# STM32L452xx register map
File version: 1.0
Registers are 32-bit, access not given, reset 0x0 unless marked. A register's access mark holds for its fields unless they carry their own. Offsets are from the block's base; [hi:lo] are bit positions; {n}, {i} and the like mark numbered series.

## SAI1
Base 0x40015400
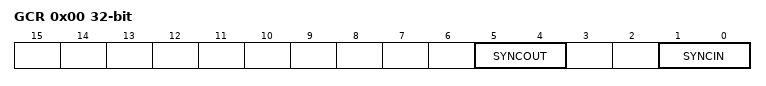
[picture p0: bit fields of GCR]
0x00 GCR
  [5:4] SYNCOUT, [1:0] SYNCIN
0x04 CR1A
0x08 CR2A
0x10 FRCRA
0x1C SLOTRA
0x24 CR1B
0x28 CR2B
0x2C IMRA
0x30 FRCRB
0x3C SLOTRB
0x40 SRA
0x4C IMRB
0x58 CLRFRA
0x60 SRB
0x74 DRA
0x78 CLRFRB
0x94 DRB

## DFSDM1
Base 0x40016000
0x00 CHCFGR10
  [31] DFSDMEN, [31] DFSDMEN, [31] DFSDMEN, [31] DFSDMEN, [31] DFSDMEN, [31] DFSDMEN, [30] CKOUTSRC, [30] CKOUTSRC, [30] CKOUTSRC, [30] CKOUTSRC, [30] CKOUTSRC, [30] CKOUTSRC, [23:22] AWFORD, [23:22] AWFORD, [23:22] AWFORD, [23:22] AWFORD, [23:22] AWFORD, [23:22] AWFORD, [23:16] CKOUTDIV, [20:16] AWFOSR, [23:16] CKOUTDIV, [31:16] INDAT1, [20:16] AWFOSR, [23:16] CKOUTDIV, [31:16] INDAT1, [20:16] AWFOSR, [23:16] CKOUTDIV, [31:16] INDAT1, [20:16] AWFOSR, [31:16] INDAT1, [23:16] CKOUTDIV, [20:16] AWFOSR, [31:16] INDAT1, [23:16] CKOUTDIV, [20:16] AWFOSR, [31:16] INDAT1, [15:14] DATPACK, [15:14] DATPACK, [15:14] DATPACK, [15:14] DATPACK, [15:14] DATPACK, [15:14] DATPACK, [13:12] DATMPX, [15:12] BKSCD, [13:12] DATMPX, [15:12] BKSCD, [13:12] DATMPX, [15:12] BKSCD, [13:12] DATMPX, [15:12] BKSCD, [13:12] DATMPX, [15:12] BKSCD, [13:12] DATMPX, [15:12] BKSCD, [8] CHINSEL, [31:8] OFFSET, [8] CHINSEL, [31:8] OFFSET, [8] CHINSEL, [31:8] OFFSET, [8] CHINSEL, [31:8] OFFSET, [8] CHINSEL, [31:8] OFFSET, [8] CHINSEL, [31:8] OFFSET, [7] CHEN, [7] CHEN, [7] CHEN, [7] CHEN, [7] CHEN, [7] CHEN, [6] CKABEN, [6] CKABEN, [6] CKABEN, [6] CKABEN, [6] CKABEN, [6] CKABEN, [5] SCDEN, [5] SCDEN, [5] SCDEN, [5] SCDEN, [5] SCDEN, [5] SCDEN, [7:3] DTRBS, [7:3] DTRBS, [7:3] DTRBS, [7:3] DTRBS, [7:3] DTRBS, [7:3] DTRBS, [3:2] SPICKSEL, [3:2] SPICKSEL, [3:2] SPICKSEL, [3:2] SPICKSEL, [3:2] SPICKSEL, [3:2] SPICKSEL, [1:0] SITP, [7:0] SCDT, [1:0] SITP, [15:0] INDAT0, [7:0] SCDT, [1:0] SITP, [15:0] INDAT0, [7:0] SCDT, [1:0] SITP, [15:0] INDAT0, [7:0] SCDT, [15:0] INDAT0, [1:0] SITP, [7:0] SCDT, [15:0] INDAT0, [1:0] SITP, [7:0] SCDT, [15:0] INDAT0
0x04 CHCFGR20
0x0C CHAWSCDR0
0x18 CHWDATAR0
0x20 CHCFGR11
0x24 CHCFGR21
0x28 CHDATINR0
0x2C CHAWSCDR1
0x38 CHWDATAR1
0x40 CHCFGR12
0x44 CHCFGR22
0x48 CHDATINR1
0x4C CHAWSCDR2
0x58 CHWDATAR2
0x60 CHCFGR13
0x64 CHCFGR23
0x68 CHDATINR2
0x6C CHAWSCDR3
0x78 CHWDATAR3
0x88 CHDATINR3
0x100 CHCFGR10
0x104 CHCFGR20
0x10C CHAWSCDR0
0x118 CHWDATAR0
0x128 CHDATINR0
0x180 CHCFGR11
0x184 CHCFGR21
0x18C CHAWSCDR1
0x198 CHWDATAR1
0x1A8 CHDATINR1

## DMA1
Base 0x40020000
Same registers: DMA2 0x40020400
0x00 ISR
  [4n-1] TEIF{n} (n=1..7), [4n-1] CTEIF{n} (n=1..7), [4n-2] HTIF{n} (n=1..7), [4n-2] CHTIF{n} (n=1..7), [4n-3] TCIF{n} (n=1..7), [4n-3] CTCIF{n} (n=1..7), [4n-4] GIF{n} (n=1..7), [4n-4] CGIF{n} (n=1..7), [14] MEM2MEM, [14] MEM2MEM, [14] MEM2MEM, [14] MEM2MEM, [14] MEM2MEM, [14] MEM2MEM, [14] MEM2MEM, [14] MEM2MEM, [14] MEM2MEM, [14] MEM2MEM, [14] MEM2MEM, [14] MEM2MEM, [14] MEM2MEM, [14] MEM2MEM, [13:12] PL, [13:12] PL, [13:12] PL, [13:12] PL, [13:12] PL, [13:12] PL, [13:12] PL, [13:12] PL, [13:12] PL, [13:12] PL, [13:12] PL, [13:12] PL, [13:12] PL, [13:12] PL, [11:10] MSIZE, [11:10] MSIZE, [11:10] MSIZE, [11:10] MSIZE, [11:10] MSIZE, [11:10] MSIZE, [11:10] MSIZE, [11:10] MSIZE, [11:10] MSIZE, [11:10] MSIZE, [11:10] MSIZE, [11:10] MSIZE, [11:10] MSIZE, [11:10] MSIZE, [9:8] PSIZE, [9:8] PSIZE, [9:8] PSIZE, [9:8] PSIZE, [9:8] PSIZE, [9:8] PSIZE, [9:8] PSIZE, [9:8] PSIZE, [9:8] PSIZE, [9:8] PSIZE, [9:8] PSIZE, [9:8] PSIZE, [9:8] PSIZE, [9:8] PSIZE, [7] MINC, [7] MINC, [7] MINC, [7] MINC, [7] MINC, [7] MINC, [7] MINC, [7] MINC, [7] MINC, [7] MINC, [7] MINC, [7] MINC, [7] MINC, [7] MINC, [6] PINC, [6] PINC, [6] PINC, [6] PINC, [6] PINC, [6] PINC, [6] PINC, [6] PINC, [6] PINC, [6] PINC, [6] PINC, [6] PINC, [6] PINC, [6] PINC, [5] CIRC, [5] CIRC, [5] CIRC, [5] CIRC, [5] CIRC, [5] CIRC, [5] CIRC, [5] CIRC, [5] CIRC, [5] CIRC, [5] CIRC, [5] CIRC, [5] CIRC, [5] CIRC, [4] DIR, [4] DIR, [4] DIR, [4] DIR, [4] DIR, [4] DIR, [4] DIR, [4] DIR, [4] DIR, [4] DIR, [4] DIR, [4] DIR, [4] DIR, [4] DIR, [3] TEIE, [3] TEIE, [3] TEIE, [3] TEIE, [3] TEIE, [3] TEIE, [3] TEIE, [3] TEIE, [3] TEIE, [3] TEIE, [3] TEIE, [3] TEIE, [3] TEIE, [3] TEIE, [2] HTIE, [2] HTIE, [2] HTIE, [2] HTIE, [2] HTIE, [2] HTIE, [2] HTIE, [2] HTIE, [2] HTIE, [2] HTIE, [2] HTIE, [2] HTIE, [2] HTIE, [2] HTIE, [1] TCIE, [1] TCIE, [1] TCIE, [1] TCIE, [1] TCIE, [1] TCIE, [1] TCIE, [1] TCIE, [1] TCIE, [1] TCIE, [1] TCIE, [1] TCIE, [1] TCIE, [1] TCIE, [0] EN, [0] EN, [15:0] NDT, [15:0] NDT, [31:0] PA, [31:0] PA, [0] EN, [0] EN, [31:0] MA, [15:0] NDT, [31:0] MA, [15:0] NDT, [31:0] PA, [31:0] PA, [0] EN, [0] EN, [31:0] MA, [15:0] NDT, [31:0] MA, [15:0] NDT, [31:0] PA, [31:0] PA, [0] EN, [0] EN, [31:0] MA, [15:0] NDT, [31:0] MA, [15:0] NDT, [31:0] PA, [31:0] PA, [0] EN, [0] EN, [31:0] MA, [15:0] NDT, [31:0] MA, [15:0] NDT, [31:0] PA, [31:0] PA, [0] EN, [0] EN, [31:0] MA, [15:0] NDT, [31:0] MA, [15:0] NDT, [31:0] PA, [31:0] PA, [0] EN, [0] EN, [31:0] MA, [15:0] NDT, [31:0] MA, [15:0] NDT, [31:0] PA, [31:0] PA, [31:0] MA, [31:0] MA
0x04 IFCR
0x08 CCR1
0x0C CNDTR1
{0x0+0x14*i} CPAR{i} (i=1..7)
0x1C CCR2
{0xC+0x14*i} CMAR{i} (i=1..7)
0x20 CNDTR2
0x30 CCR3
0x34 CNDTR3
0x44 CCR4
0x48 CNDTR4
0x58 CCR5
0x5C CNDTR5
0x6C CCR6
0x70 CNDTR6
0x80 CCR7
0x84 CNDTR7
